VERSION ""

NS_ :

BS_:

BU_:

BO_ 2550650356 EPT2DCDC: 8 Vector__XXX
 SG_ DC_Control : 32|8@1- (1,0) [0|0] "" Vector__XXX

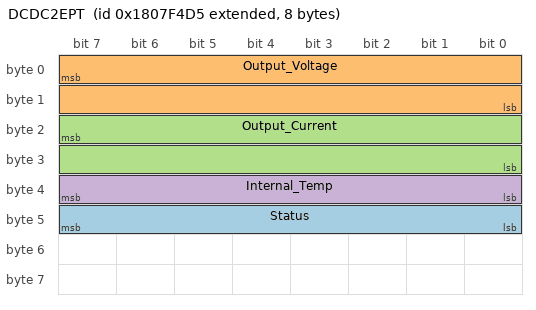
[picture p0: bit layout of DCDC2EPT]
BO_ 2550658261 DCDC2EPT: 8 Vector__XXX
 SG_ Status : 47|8@0+ (1,0) [0|0] "" Vector__XXX
 SG_ Output_Voltage : 7|16@0+ (0.1,0) [0|0] "V" Vector__XXX
 SG_ Output_Current : 23|16@0+ (0.1,0) [0|0] "A" Vector__XXX
 SG_ Internal_Temp : 39|8@0+ (1,-40) [0|0] "C" Vector__XXX
